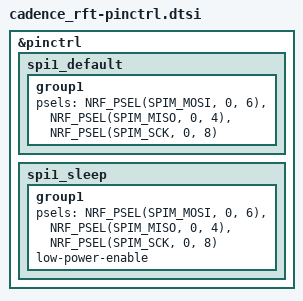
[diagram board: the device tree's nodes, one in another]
// Copyright (c) 2026
// SPDX-License-Identifier: Apache-2.0
//
// Pin assignments come straight from RideFormTracker PCB v1.1 — this is the
// same physical board as the FindMyTag bring-up target, only the payload
// firmware differs.

&pinctrl {
	/* SPIM1 — LSM6DSV (MOSI P0.06, MISO P0.04, SCK P0.08; CS is a GPIO) */
	spi1_default: spi1_default {
		group1 {
			psels = <NRF_PSEL(SPIM_MOSI, 0, 6)>,
				<NRF_PSEL(SPIM_MISO, 0, 4)>,
				<NRF_PSEL(SPIM_SCK, 0, 8)>;
		};
	};

	spi1_sleep: spi1_sleep {
		group1 {
			psels = <NRF_PSEL(SPIM_MOSI, 0, 6)>,
				<NRF_PSEL(SPIM_MISO, 0, 4)>,
				<NRF_PSEL(SPIM_SCK, 0, 8)>;
			low-power-enable;
		};
	};
};
